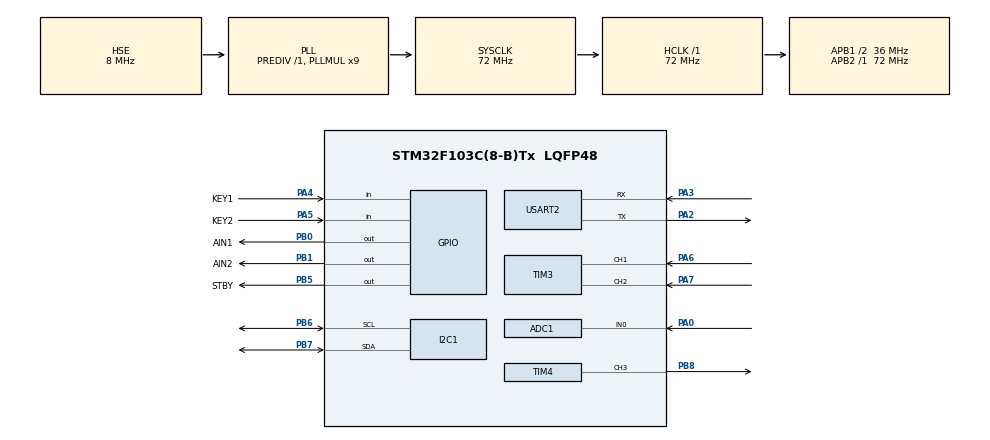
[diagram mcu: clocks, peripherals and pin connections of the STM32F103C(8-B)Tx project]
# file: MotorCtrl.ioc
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ADC1.Channel-0\#ChannelRegularConversion=ADC_CHANNEL_0
ADC1.NbrOfConversion=1
ADC1.NbrOfConversionFlag=1
ADC1.Rank-0\#ChannelRegularConversion=1
ADC1.SamplingTime-0\#ChannelRegularConversion=ADC_SAMPLETIME_55CYCLES_5
ADC1.master=1
Dma.Request0=USART2_RX
Dma.Request1=USART2_TX
Dma.USART2_RX.0.Direction=DMA_PERIPH_TO_MEMORY
Dma.USART2_RX.0.Instance=DMA1_Channel6
Dma.USART2_RX.0.MemDataAlignment=DMA_MDATAALIGN_BYTE
Dma.USART2_RX.0.MemInc=DMA_MINC_ENABLE
Dma.USART2_RX.0.Mode=DMA_CIRCULAR
Dma.USART2_RX.0.PeriphDataAlignment=DMA_PDATAALIGN_BYTE
Dma.USART2_RX.0.PeriphInc=DMA_PINC_DISABLE
Dma.USART2_RX.0.Priority=DMA_PRIORITY_LOW
Dma.USART2_TX.1.Direction=DMA_MEMORY_TO_PERIPH
Dma.USART2_TX.1.Instance=DMA1_Channel7
Dma.USART2_TX.1.MemDataAlignment=DMA_MDATAALIGN_BYTE
Dma.USART2_TX.1.MemInc=DMA_MINC_ENABLE
Dma.USART2_TX.1.Mode=DMA_NORMAL
Dma.USART2_TX.1.PeriphDataAlignment=DMA_PDATAALIGN_BYTE
Dma.USART2_TX.1.PeriphInc=DMA_PINC_DISABLE
Dma.USART2_TX.1.Priority=DMA_PRIORITY_LOW
I2C1.I2C_Mode=I2C_Fast
IWDG.Prescaler=IWDG_PRESCALER_64
IWDG.Reload=625
Mcu.Family=STM32F1
Mcu.Name=STM32F103C(8-B)Tx
Mcu.Package=LQFP48
NVIC.DMA1_Channel6_IRQn=true\:3\:0\:true\:false\:true\:false\:true\:true
NVIC.DMA1_Channel7_IRQn=true\:3\:0\:true\:false\:true\:false\:true\:true
NVIC.PriorityGroup=NVIC_PRIORITYGROUP_4
NVIC.TIM2_IRQn=true\:1\:0\:true\:false\:true\:true\:true\:true
NVIC.USART2_IRQn=true\:2\:0\:true\:false\:true\:true\:true\:true
PA0-WKUP.Signal=ADCx_IN0
PA13.Mode=Serial_Wire
PA13.Signal=SYS_JTMS-SWDIO
PA14.Mode=Serial_Wire
PA14.Signal=SYS_JTCK-SWCLK
PA2.Mode=Asynchronous
PA2.Signal=USART2_TX
PA3.Mode=Asynchronous
PA3.Signal=USART2_RX
PA4.GPIO_Label=KEY1
PA4.GPIO_PuPd=GPIO_PULLUP
PA4.Signal=GPIO_Input
PA5.GPIO_Label=KEY2
PA5.GPIO_PuPd=GPIO_PULLUP
PA5.Signal=GPIO_Input
PA6.GPIO_PuPd=GPIO_PULLUP
PA6.Signal=S_TIM3_CH1
PA7.GPIO_PuPd=GPIO_PULLUP
PA7.Signal=S_TIM3_CH2
PB0.GPIO_Label=AIN1
PB0.Signal=GPIO_Output
PB1.GPIO_Label=AIN2
PB1.Signal=GPIO_Output
PB5.GPIO_Label=STBY
PB5.Signal=GPIO_Output
PB6.Mode=I2C
PB6.Signal=I2C1_SCL
PB7.Mode=I2C
PB7.Signal=I2C1_SDA
PB8.Signal=S_TIM4_CH3
PD0-OSC_IN.Mode=HSE-External-Oscillator
PD0-OSC_IN.Signal=RCC_OSC_IN
PD1-OSC_OUT.Mode=HSE-External-Oscillator
PD1-OSC_OUT.Signal=RCC_OSC_OUT
ProjectManager.HeapSize=0x200
ProjectManager.StackSize=0x400
ProjectManager.TargetToolchain=STM32CubeIDE
RCC.ADCPresc=RCC_ADCPCLK2_DIV6
RCC.AHBFreq_Value=72000000
RCC.APB1CLKDivider=RCC_HCLK_DIV2
RCC.APB1Freq_Value=36000000
RCC.APB1TimFreq_Value=72000000
RCC.APB2Freq_Value=72000000
RCC.APB2TimFreq_Value=72000000
RCC.HCLKFreq_Value=72000000
RCC.PLLMUL=RCC_PLL_MUL9
RCC.PLLSourceVirtual=RCC_PLLSOURCE_HSE
RCC.SYSCLKFreq_VALUE=72000000
RCC.SYSCLKSource=RCC_SYSCLKSOURCE_PLLCLK
RCC.USBFreq_Value=72000000
SH.ADCx_IN0.0=ADC1_IN0,IN0
SH.S_TIM3_CH1.0=TIM3_CH1,Encoder_Interface
SH.S_TIM3_CH2.0=TIM3_CH2,Encoder_Interface
SH.S_TIM4_CH3.0=TIM4_CH3,PWM Generation3 CH3
TIM2.Period=999
TIM2.Prescaler=71
TIM3.EncoderMode=TIM_ENCODERMODE_TI12
TIM3.IC1Filter=6
TIM3.IC2Filter=6
TIM4.AutoReloadPreload=TIM_AUTORELOAD_PRELOAD_ENABLE
TIM4.Channel-PWM\ Generation3\ CH3=TIM_CHANNEL_3
TIM4.Period=3599
USART2.VirtualMode=VM_ASYNC
VP_IWDG_VS_IWDG.Mode=IWDG_Activate
VP_TIM2_VS_ClockSourceINT.Mode=Internal
VP_TIM4_VS_ClockSourceINT.Mode=Internal
board=custom

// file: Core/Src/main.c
/* USER CODE BEGIN Header */
/**
  ******************************************************************************
  * @file           : main.c
  * @brief          : Main program body
  ******************************************************************************
  * @attention
  *
  * Copyright (c) 2026 STMicroelectronics.
  * All rights reserved.
  *
  * This software is licensed under terms that can be found in the LICENSE file
  * in the root directory of this software component.
  * If no LICENSE file comes with this software, it is provided AS-IS.
  *
  ******************************************************************************
  */
/* USER CODE END Header */
#include "main.h"
#include "adc.h"
#include "dma.h"
#include "i2c.h"
#include "iwdg.h"
#include "tim.h"
#include "usart.h"
#include "gpio.h"

void SystemClock_Config(void);

int main(void)
{

  /* MCU Configuration--------------------------------------------------------*/

  /* Reset of all peripherals, Initializes the Flash interface and the Systick. */
  HAL_Init();

  /* Configure the system clock */
  SystemClock_Config();

  /* Initialize all configured peripherals */
  MX_GPIO_Init();
  MX_DMA_Init();
  MX_I2C1_Init();
  MX_USART2_UART_Init();
  MX_TIM3_Init();
  MX_TIM4_Init();
  MX_TIM2_Init();
  MX_ADC1_Init();
  MX_IWDG_Init();

  /* Infinite loop */
  while (1)
  {

    /* USER CODE BEGIN 3 */
    HAL_IWDG_Refresh(&hiwdg);
  }
  /* USER CODE END 3 */
}

void SystemClock_Config(void)
{
  RCC_OscInitTypeDef RCC_OscInitStruct = {0};
  RCC_ClkInitTypeDef RCC_ClkInitStruct = {0};
  RCC_PeriphCLKInitTypeDef PeriphClkInit = {0};

  /** Initializes the RCC Oscillators according to the specified parameters
  * in the RCC_OscInitTypeDef structure.
  */
  RCC_OscInitStruct.OscillatorType = RCC_OSCILLATORTYPE_LSI|RCC_OSCILLATORTYPE_HSE;
  RCC_OscInitStruct.HSEState = RCC_HSE_ON;
  RCC_OscInitStruct.HSEPredivValue = RCC_HSE_PREDIV_DIV1;
  RCC_OscInitStruct.HSIState = RCC_HSI_ON;
  RCC_OscInitStruct.LSIState = RCC_LSI_ON;
  RCC_OscInitStruct.PLL.PLLState = RCC_PLL_ON;
  RCC_OscInitStruct.PLL.PLLSource = RCC_PLLSOURCE_HSE;
  RCC_OscInitStruct.PLL.PLLMUL = RCC_PLL_MUL9;
  if (HAL_RCC_OscConfig(&RCC_OscInitStruct) != HAL_OK)
  {
    Error_Handler();
  }

  /** Initializes the CPU, AHB and APB buses clocks
  */
  RCC_ClkInitStruct.ClockType = RCC_CLOCKTYPE_HCLK|RCC_CLOCKTYPE_SYSCLK
                              |RCC_CLOCKTYPE_PCLK1|RCC_CLOCKTYPE_PCLK2;
  RCC_ClkInitStruct.SYSCLKSource = RCC_SYSCLKSOURCE_PLLCLK;
  RCC_ClkInitStruct.AHBCLKDivider = RCC_SYSCLK_DIV1;
  RCC_ClkInitStruct.APB1CLKDivider = RCC_HCLK_DIV2;
  RCC_ClkInitStruct.APB2CLKDivider = RCC_HCLK_DIV1;

  if (HAL_RCC_ClockConfig(&RCC_ClkInitStruct, FLASH_LATENCY_2) != HAL_OK)
  {
    Error_Handler();
  }
  PeriphClkInit.PeriphClockSelection = RCC_PERIPHCLK_ADC;
  PeriphClkInit.AdcClockSelection = RCC_ADCPCLK2_DIV6;
  if (HAL_RCCEx_PeriphCLKConfig(&PeriphClkInit) != HAL_OK)
  {
    Error_Handler();
  }
}

void Error_Handler(void)
{
  __disable_irq();
  while (1)
  {
  }
}
